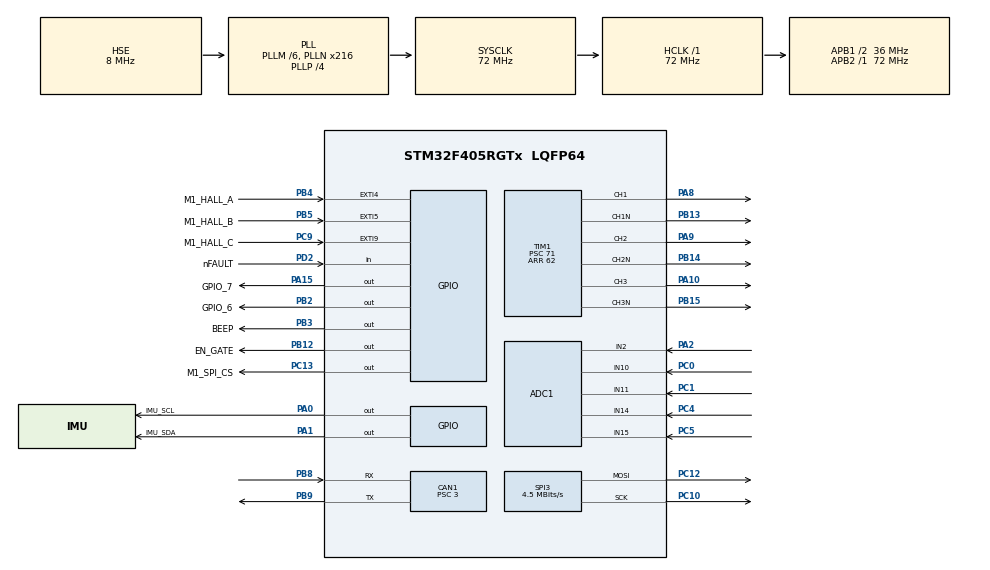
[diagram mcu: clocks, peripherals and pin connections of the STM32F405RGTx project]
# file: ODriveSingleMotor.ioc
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ADC1.Channel-0\#ChannelRegularConversion=ADC_CHANNEL_2
ADC1.Channel-1\#ChannelRegularConversion=ADC_CHANNEL_14
ADC1.ContinuousConvMode=ENABLE
ADC1.DMAContinuousRequests=ENABLE
ADC1.ExternalTrigConv=ADC_SOFTWARE_START
ADC1.NbrOfConversion=2
ADC1.NbrOfConversionFlag=1
ADC1.Rank-0\#ChannelRegularConversion=1
ADC1.Rank-1\#ChannelRegularConversion=2
ADC1.SamplingTime-0\#ChannelRegularConversion=ADC_SAMPLETIME_3CYCLES
ADC1.SamplingTime-1\#ChannelRegularConversion=ADC_SAMPLETIME_3CYCLES
ADC1.master=1
CAN1.BS1=CAN_BS1_5TQ
CAN1.BS2=CAN_BS2_6TQ
CAN1.CalculateTimeQuantum=83.33333333333334
CAN1.Prescaler=3
Dma.ADC1.0.Direction=DMA_PERIPH_TO_MEMORY
Dma.ADC1.0.FIFOMode=DMA_FIFOMODE_DISABLE
Dma.ADC1.0.Instance=DMA2_Stream0
Dma.ADC1.0.MemDataAlignment=DMA_MDATAALIGN_HALFWORD
Dma.ADC1.0.MemInc=DMA_MINC_ENABLE
Dma.ADC1.0.Mode=DMA_CIRCULAR
Dma.ADC1.0.PeriphDataAlignment=DMA_PDATAALIGN_HALFWORD
Dma.ADC1.0.PeriphInc=DMA_PINC_DISABLE
Dma.ADC1.0.Priority=DMA_PRIORITY_LOW
Dma.Request0=ADC1
Dma.Request1=SPI3_TX
Dma.SPI3_TX.1.Direction=DMA_MEMORY_TO_PERIPH
Dma.SPI3_TX.1.FIFOMode=DMA_FIFOMODE_DISABLE
Dma.SPI3_TX.1.Instance=DMA1_Stream5
Dma.SPI3_TX.1.MemDataAlignment=DMA_MDATAALIGN_BYTE
Dma.SPI3_TX.1.MemInc=DMA_MINC_ENABLE
Dma.SPI3_TX.1.Mode=DMA_CIRCULAR
Dma.SPI3_TX.1.PeriphDataAlignment=DMA_PDATAALIGN_BYTE
Dma.SPI3_TX.1.PeriphInc=DMA_PINC_DISABLE
Dma.SPI3_TX.1.Priority=DMA_PRIORITY_LOW
Mcu.Family=STM32F4
Mcu.Name=STM32F405RGTx
Mcu.Package=LQFP64
NVIC.CAN1_RX0_IRQn=true\:1\:0\:true\:false\:true\:true\:true
NVIC.EXTI4_IRQn=true\:1\:0\:true\:false\:true\:true\:true
NVIC.EXTI9_5_IRQn=true\:1\:0\:true\:false\:true\:true\:true
NVIC.PriorityGroup=NVIC_PRIORITYGROUP_4
NVIC.TIM1_UP_TIM10_IRQn=true\:1\:0\:true\:false\:true\:true\:true
NVIC.TIM6_DAC_IRQn=true\:0\:0\:true\:false\:true\:true\:true
NVIC.TIM7_IRQn=true\:0\:0\:true\:false\:true\:true\:true
PA0-WKUP.GPIO_Label=IMU_SCL
PA0-WKUP.GPIO_ModeDefaultOutputPP=GPIO_MODE_OUTPUT_PP
PA0-WKUP.GPIO_PuPd=GPIO_PULLUP
PA0-WKUP.GPIO_Speed=GPIO_SPEED_FREQ_HIGH
PA0-WKUP.PinState=GPIO_PIN_SET
PA0-WKUP.Signal=GPIO_Output
PA1.GPIO_Label=IMU_SDA
PA1.GPIO_ModeDefaultOutputPP=GPIO_MODE_OUTPUT_PP
PA1.GPIO_PuPd=GPIO_PULLUP
PA1.GPIO_Speed=GPIO_SPEED_FREQ_HIGH
PA1.PinState=GPIO_PIN_SET
PA1.Signal=GPIO_Output
PA10.Signal=S_TIM1_CH3
PA13.Mode=Serial_Wire
PA13.Signal=SYS_JTMS-SWDIO
PA14.Mode=Serial_Wire
PA14.Signal=SYS_JTCK-SWCLK
PA15.GPIO_Label=GPIO_7
PA15.Signal=GPIO_Output
PA2.Signal=ADCx_IN2
PA8.Signal=S_TIM1_CH1
PA9.Signal=S_TIM1_CH2
PB12.GPIO_Label=EN_GATE
PB12.GPIO_PuPd=GPIO_NOPULL
PB12.Signal=GPIO_Output
PB13.Mode=PWM Generation1 CH1 CH1N
PB13.Signal=TIM1_CH1N
PB14.Mode=PWM Generation2 CH2 CH2N
PB14.Signal=TIM1_CH2N
PB15.Mode=PWM Generation3 CH3 CH3N
PB15.Signal=TIM1_CH3N
PB2.GPIO_Label=GPIO_6
PB2.Signal=GPIO_Output
PB3.GPIO_Label=BEEP
PB3.GPIO_ModeDefaultOutputPP=GPIO_MODE_OUTPUT_OD
PB3.GPIO_PuPd=GPIO_PULLUP
PB3.PinState=GPIO_PIN_SET
PB3.Signal=GPIO_Output
PB4.GPIO_Label=M1_HALL_A
PB4.GPIO_ModeDefaultEXTI=GPIO_MODE_IT_RISING_FALLING
PB4.GPIO_PuPd=GPIO_PULLUP
PB4.Signal=GPXTI4
PB5.GPIO_Label=M1_HALL_B
PB5.GPIO_ModeDefaultEXTI=GPIO_MODE_IT_RISING_FALLING
PB5.GPIO_PuPd=GPIO_PULLUP
PB5.Signal=GPXTI5
PB8.Mode=Master
PB8.Signal=CAN1_RX
PB9.Mode=Master
PB9.Signal=CAN1_TX
PC0.Signal=ADCx_IN10
PC1.Signal=ADCx_IN11
PC10.Mode=TX_Only_Simplex_Unidirect_Master
PC10.Signal=SPI3_SCK
PC12.Mode=TX_Only_Simplex_Unidirect_Master
PC12.Signal=SPI3_MOSI
PC13-ANTI_TAMP.GPIO_Label=M1_SPI_CS
PC13-ANTI_TAMP.Signal=GPIO_Output
PC4.Signal=ADCx_IN14
PC5.Signal=ADCx_IN15
PC9.GPIO_Label=M1_HALL_C
PC9.GPIO_ModeDefaultEXTI=GPIO_MODE_IT_RISING_FALLING
PC9.GPIO_PuPd=GPIO_PULLUP
PC9.Signal=GPXTI9
PD2.GPIO_Label=nFAULT
PD2.GPIO_PuPd=GPIO_PULLUP
PD2.Signal=GPIO_Input
PH0-OSC_IN.Mode=HSE-External-Oscillator
PH0-OSC_IN.Signal=RCC_OSC_IN
PH1-OSC_OUT.Mode=HSE-External-Oscillator
PH1-OSC_OUT.Signal=RCC_OSC_OUT
ProjectManager.HeapSize=0x200
ProjectManager.StackSize=0x400
ProjectManager.TargetToolchain=Makefile
RCC.48MHZClocksFreq_Value=72000000
RCC.AHBFreq_Value=72000000
RCC.APB1CLKDivider=RCC_HCLK_DIV2
RCC.APB1Freq_Value=36000000
RCC.APB1TimFreq_Value=72000000
RCC.APB2Freq_Value=72000000
RCC.APB2TimFreq_Value=72000000
RCC.CortexFreq_Value=72000000
RCC.HCLKFreq_Value=72000000
RCC.HSE_VALUE=8000000
RCC.HSI_VALUE=16000000
RCC.LSE_VALUE=32768
RCC.PLLM=6
RCC.PLLN=216
RCC.PLLP=RCC_PLLP_DIV4
RCC.PLLSourceVirtual=RCC_PLLSOURCE_HSE
RCC.SYSCLKFreq_VALUE=72000000
RCC.SYSCLKSource=RCC_SYSCLKSOURCE_PLLCLK
RCC.VCOOutputFreq_Value=288000000
SH.ADCx_IN10.0=ADC1_IN10,IN10
SH.ADCx_IN11.0=ADC1_IN11,IN11
SH.ADCx_IN14.0=ADC1_IN14,IN14
SH.ADCx_IN15.0=ADC1_IN15,IN15
SH.ADCx_IN2.0=ADC1_IN2,IN2
SH.S_TIM1_CH1.0=TIM1_CH1,PWM Generation1 CH1 CH1N
SH.S_TIM1_CH2.0=TIM1_CH2,PWM Generation2 CH2 CH2N
SH.S_TIM1_CH3.0=TIM1_CH3,PWM Generation3 CH3 CH3N
SPI3.BaudRatePrescaler=SPI_BAUDRATEPRESCALER_8
SPI3.CLKPhase=SPI_PHASE_2EDGE
SPI3.CLKPolarity=SPI_POLARITY_LOW
SPI3.CalculateBaudRate=4.5 MBits/s
SPI3.DataSize=SPI_DATASIZE_8BIT
SPI3.Direction=SPI_DIRECTION_2LINES
SPI3.Mode=SPI_MODE_MASTER
SPI3.VirtualType=VM_MASTER
TIM1.AutoReloadPreload=TIM_AUTORELOAD_PRELOAD_ENABLE
TIM1.Channel-PWM\ Generation1\ CH1\ CH1N=TIM_CHANNEL_1
TIM1.Channel-PWM\ Generation2\ CH2\ CH2N=TIM_CHANNEL_2
TIM1.Channel-PWM\ Generation3\ CH3\ CH3N=TIM_CHANNEL_3
TIM1.DeadTime=2
TIM1.Period=62
TIM1.Prescaler=71
TIM10.AutoReloadPreload=TIM_AUTORELOAD_PRELOAD_ENABLE
TIM10.Period=999
TIM10.Prescaler=71
TIM6.AutoReloadPreload=TIM_AUTORELOAD_PRELOAD_ENABLE
TIM6.Period=9999
TIM6.Prescaler=719
TIM7.AutoReloadPreload=TIM_AUTORELOAD_PRELOAD_ENABLE
TIM7.Period=999
TIM7.Prescaler=71
VP_TIM10_VS_ClockSourceINT.Mode=Enable_Timer
VP_TIM1_VS_ClockSourceINT.Mode=Internal
VP_TIM6_VS_ClockSourceINT.Mode=Enable_Timer
VP_TIM7_VS_ClockSourceINT.Mode=Enable_Timer
board=custom

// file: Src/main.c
/* USER CODE BEGIN Header */
/**
  ******************************************************************************
  * @file           : main.c
  * @brief          : Main program body
  ******************************************************************************
  * @attention
  *
  * <h2><center>&copy; Copyright (c) 2021 STMicroelectronics.
  * All rights reserved.</center></h2>
  *
  * This software component is licensed by ST under BSD 3-Clause license,
  * the "License"; You may not use this file except in compliance with the
  * License. You may obtain a copy of the License at:
  *                        opensource.org/licenses/BSD-3-Clause
  *
  ******************************************************************************
  */
/* USER CODE END Header */

#include "main.h"
#include "adc.h"
#include "can.h"
#include "dma.h"
#include "spi.h"
#include "tim.h"
#include "gpio.h"

/* USER CODE BEGIN Includes */
#include "user_main.h"
/* USER CODE END Includes */

void SystemClock_Config(void);

int main(void)
{

  /* MCU Configuration--------------------------------------------------------*/

  /* Reset of all peripherals, Initializes the Flash interface and the Systick. */
  HAL_Init();

  /* Configure the system clock */
  SystemClock_Config();

  /* Initialize all configured peripherals */
  MX_GPIO_Init();
  MX_DMA_Init();
  MX_ADC1_Init();
  MX_SPI3_Init();
  MX_TIM1_Init();
  MX_TIM7_Init();
  MX_CAN1_Init();
  MX_TIM6_Init();
  MX_TIM10_Init();
  /* USER CODE BEGIN 2 */
  user_setup();
  /* USER CODE END 2 */

  /* Infinite loop */
  /* USER CODE BEGIN WHILE */
  while (1)
  {
    user_loop();
    /* USER CODE END WHILE */

  }
}

void SystemClock_Config(void)
{
  RCC_OscInitTypeDef RCC_OscInitStruct = {0};
  RCC_ClkInitTypeDef RCC_ClkInitStruct = {0};

  /** Configure the main internal regulator output voltage
  */
  __HAL_RCC_PWR_CLK_ENABLE();
  __HAL_PWR_VOLTAGESCALING_CONFIG(PWR_REGULATOR_VOLTAGE_SCALE1);
  /** Initializes the CPU, AHB and APB busses clocks
  */
  RCC_OscInitStruct.OscillatorType = RCC_OSCILLATORTYPE_HSE;
  RCC_OscInitStruct.HSEState = RCC_HSE_ON;
  RCC_OscInitStruct.PLL.PLLState = RCC_PLL_ON;
  RCC_OscInitStruct.PLL.PLLSource = RCC_PLLSOURCE_HSE;
  RCC_OscInitStruct.PLL.PLLM = 6;
  RCC_OscInitStruct.PLL.PLLN = 216;
  RCC_OscInitStruct.PLL.PLLP = RCC_PLLP_DIV4;
  RCC_OscInitStruct.PLL.PLLQ = 4;
  if (HAL_RCC_OscConfig(&RCC_OscInitStruct) != HAL_OK)
  {
    Error_Handler();
  }
  /** Initializes the CPU, AHB and APB busses clocks
  */
  RCC_ClkInitStruct.ClockType = RCC_CLOCKTYPE_HCLK|RCC_CLOCKTYPE_SYSCLK
                              |RCC_CLOCKTYPE_PCLK1|RCC_CLOCKTYPE_PCLK2;
  RCC_ClkInitStruct.SYSCLKSource = RCC_SYSCLKSOURCE_PLLCLK;
  RCC_ClkInitStruct.AHBCLKDivider = RCC_SYSCLK_DIV1;
  RCC_ClkInitStruct.APB1CLKDivider = RCC_HCLK_DIV2;
  RCC_ClkInitStruct.APB2CLKDivider = RCC_HCLK_DIV1;

  if (HAL_RCC_ClockConfig(&RCC_ClkInitStruct, FLASH_LATENCY_2) != HAL_OK)
  {
    Error_Handler();
  }
}

void Error_Handler(void)
{
}

/************************ (C) COPYRIGHT STMicroelectronics *****END OF FILE****/
